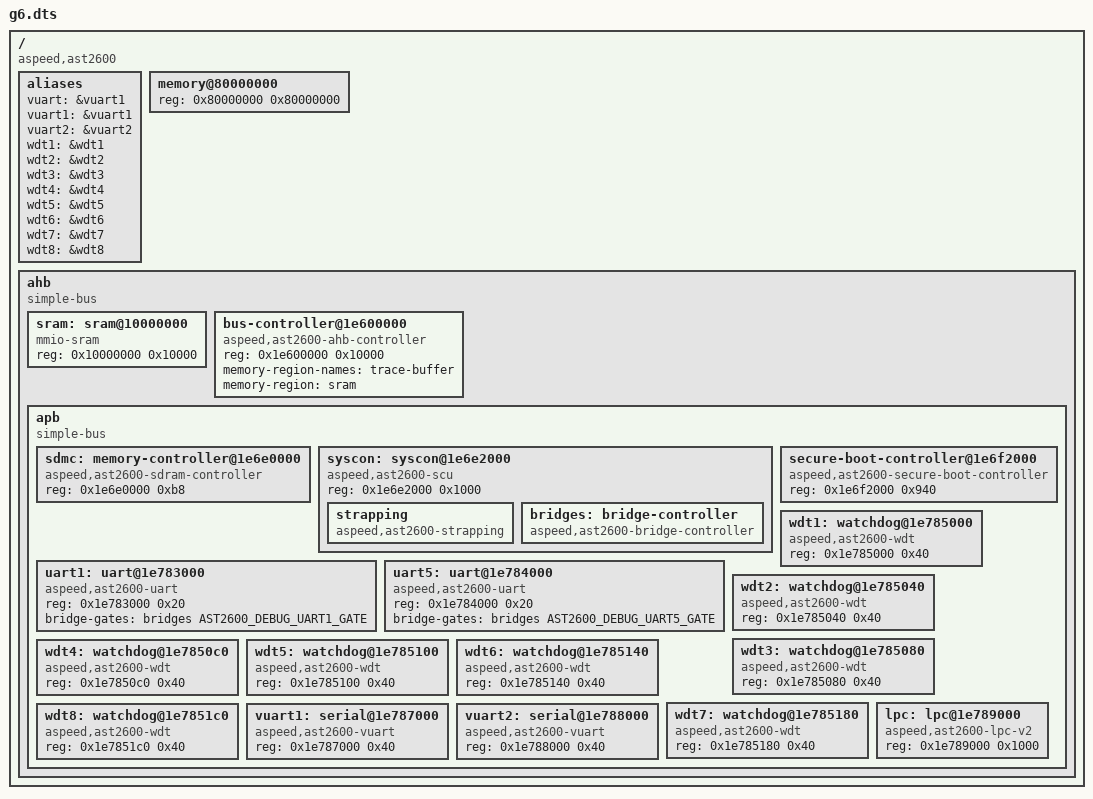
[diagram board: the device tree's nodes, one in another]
// SPDX-License-Identifier: Apache-2.0
// Copyright 2021 IBM Corp.

#include "soc/bridge-ids.h"

/dts-v1/;

/ {
	compatible = "aspeed,ast2600";
	#address-cells = <1>;
	#size-cells = <1>;

	aliases {
		vuart = &vuart1;
		vuart1 = &vuart1;
		vuart2 = &vuart2;
		wdt1 = &wdt1;
		wdt2 = &wdt2;
		wdt3 = &wdt3;
		wdt4 = &wdt4;
		wdt5 = &wdt5;
		wdt6 = &wdt6;
		wdt7 = &wdt7;
		wdt8 = &wdt8;
	};

	memory@80000000 {
		device_type = "memory";
		reg = <0x80000000 0x80000000>;
	};

	ahb {
		compatible = "simple-bus";
		#address-cells = <1>;
		#size-cells = <1>;
		ranges;

		sram: sram@10000000 {
			compatible = "mmio-sram";
			reg = <0x10000000 0x10000>;	// 64K
		};

		bus-controller@1e600000 {
			compatible = "aspeed,ast2600-ahb-controller";
			reg = <0x1e600000 0x10000>;

			memory-region-names = "trace-buffer";
			// Technically should point to a node under reserved-memory, but SRAM isn't
			// mapped anyway which is why we're using it.
			memory-region = <&sram>;
		};

		apb {
			compatible = "simple-bus";
			#address-cells = <1>;
			#size-cells = <1>;

			sdmc: memory-controller@1e6e0000 {
				compatible = "aspeed,ast2600-sdram-controller";
				reg = <0x1e6e0000 0xb8>;
			};

			syscon: syscon@1e6e2000 {
				compatible = "aspeed,ast2600-scu", "syscon", "simple-mfd";
				reg = <0x1e6e2000 0x1000>;

				strapping {
					compatible = "aspeed,ast2600-strapping";
				};

				bridges: bridge-controller {
					compatible = "aspeed,ast2600-bridge-controller";
				};
			};

			secure-boot-controller@1e6f2000 {
				compatible = "aspeed,ast2600-secure-boot-controller";
				reg = <0x1e6f2000 0x940>;
			};

			uart1: uart@1e783000 {
				compatible = "aspeed,ast2600-uart", "ns16550a", "bridge-controller";
				reg = <0x1e783000 0x20>;
				bridge-gates = <&bridges AST2600_DEBUG_UART1_GATE>;
			};

			uart5: uart@1e784000 {
				compatible = "aspeed,ast2600-uart", "ns16550a", "bridge-controller";
				reg = <0x1e784000 0x20>;
				bridge-gates = <&bridges AST2600_DEBUG_UART5_GATE>;
			};

			wdt1: watchdog@1e785000 {
				compatible = "aspeed,ast2600-wdt";
				reg = <0x1e785000 0x40>;
			};

			wdt2: watchdog@1e785040 {
				compatible = "aspeed,ast2600-wdt";
				reg = <0x1e785040 0x40>;
			};

			wdt3: watchdog@1e785080 {
				compatible = "aspeed,ast2600-wdt";
				reg = <0x1e785080 0x40>;
			};

			wdt4: watchdog@1e7850c0 {
				compatible = "aspeed,ast2600-wdt";
				reg = <0x1e7850c0 0x40>;
			};

			wdt5: watchdog@1e785100 {
				compatible = "aspeed,ast2600-wdt";
				reg = <0x1e785100 0x40>;
			};

			wdt6: watchdog@1e785140 {
				compatible = "aspeed,ast2600-wdt";
				reg = <0x1e785140 0x40>;
			};

			wdt7: watchdog@1e785180 {
				compatible = "aspeed,ast2600-wdt";
				reg = <0x1e785180 0x40>;
			};

			wdt8: watchdog@1e7851c0 {
				compatible = "aspeed,ast2600-wdt";
				reg = <0x1e7851c0 0x40>;
			};

			vuart1: serial@1e787000 {
				compatible = "aspeed,ast2600-vuart";
				reg = <0x1e787000 0x40>;
			};

			vuart2: serial@1e788000 {
				compatible = "aspeed,ast2600-vuart";
				reg = <0x1e788000 0x40>;
			};

			lpc: lpc@1e789000 {
				compatible = "aspeed,ast2600-lpc-v2", "syscon", "simple-mfd";
				reg = <0x1e789000 0x1000>;
			};
		};
	};
};
